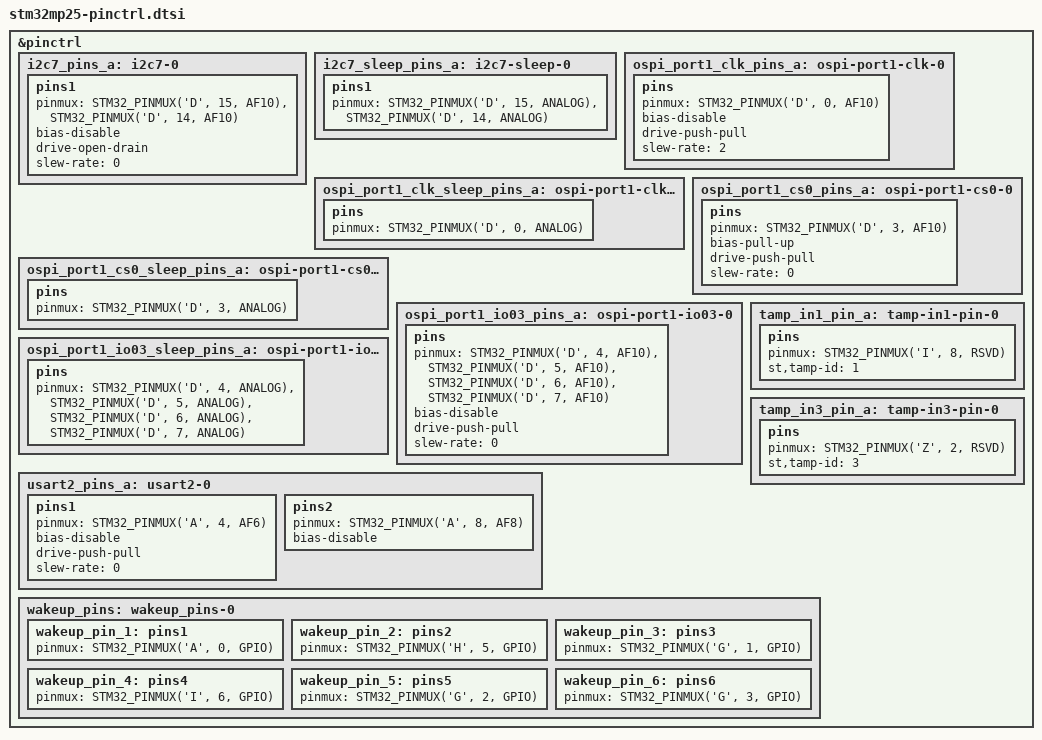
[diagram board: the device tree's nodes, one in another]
// SPDX-License-Identifier: (GPL-2.0+ OR BSD-3-Clause)
/*
 * Copyright (C) STMicroelectronics 2021 - All Rights Reserved
 * Author: Alexandre Torgue <alexandre.torgue@foss.st.com> for STMicroelectronics.
 */
#include <dt-bindings/pinctrl/stm32-pinfunc.h>

&pinctrl {
	i2c7_pins_a: i2c7-0 {
		pins1 {
			pinmux = <STM32_PINMUX('D', 15, AF10)>, /* I2C7_SCL */
				 <STM32_PINMUX('D', 14, AF10)>; /* I2C7_SDA */
			bias-disable;
			drive-open-drain;
			slew-rate = <0>;
		};
	};

	i2c7_sleep_pins_a: i2c7-sleep-0 {
		pins1 {
			pinmux = <STM32_PINMUX('D', 15, ANALOG)>, /* I2C7_SCL */
				 <STM32_PINMUX('D', 14, ANALOG)>; /* I2C7_SDA */
		};
	};

	ospi_port1_clk_pins_a: ospi-port1-clk-0 {
		pins {
			pinmux = <STM32_PINMUX('D', 0, AF10)>; /* OSPI1_CLK */
			bias-disable;
			drive-push-pull;
			slew-rate = <2>;
		};
	};

	ospi_port1_clk_sleep_pins_a: ospi-port1-clk-sleep-0 {
		pins {
			pinmux = <STM32_PINMUX('D', 0, ANALOG)>; /* OSPI1_CLK */
		};
	};

	ospi_port1_cs0_pins_a: ospi-port1-cs0-0 {
		pins {
			pinmux = <STM32_PINMUX('D', 3, AF10)>; /* OSPI_NCS0 */
			bias-pull-up;
			drive-push-pull;
			slew-rate = <0>;
		};
	};

	ospi_port1_cs0_sleep_pins_a: ospi-port1-cs0-sleep-0 {
		pins {
			pinmux = <STM32_PINMUX('D', 3, ANALOG)>; /* OSPI_NCS0 */
		};
	};

	ospi_port1_io03_pins_a: ospi-port1-io03-0 {
		pins {
			pinmux = <STM32_PINMUX('D', 4, AF10)>, /* OSPI_IO0 */
				 <STM32_PINMUX('D', 5, AF10)>, /* OSPI_IO1 */
				 <STM32_PINMUX('D', 6, AF10)>, /* OSPI_IO2 */
				 <STM32_PINMUX('D', 7, AF10)>; /* OSPI_IO3 */
			bias-disable;
			drive-push-pull;
			slew-rate = <0>;
		};
	};

	ospi_port1_io03_sleep_pins_a: ospi-port1-io03-sleep-0 {
		pins {
			pinmux = <STM32_PINMUX('D', 4, ANALOG)>, /* OSPI_IO0 */
				 <STM32_PINMUX('D', 5, ANALOG)>, /* OSPI_IO1 */
				 <STM32_PINMUX('D', 6, ANALOG)>, /* OSPI_IO2 */
				 <STM32_PINMUX('D', 7, ANALOG)>; /* OSPI_IO3 */
		};
	};

	tamp_in1_pin_a: tamp-in1-pin-0 {
		pins {
			pinmux = <STM32_PINMUX('I', 8, RSVD)>;
			st,tamp-id = <1>;
		};
	};

	tamp_in3_pin_a: tamp-in3-pin-0 {
		pins {
			pinmux = <STM32_PINMUX('Z', 2, RSVD)>;
			st,tamp-id = <3>;
		};
	};

	usart2_pins_a: usart2-0 {
		pins1 {
			pinmux = <STM32_PINMUX('A', 4, AF6)>; /* USART2_TX */
			bias-disable;
			drive-push-pull;
			slew-rate = <0>;
		};
		pins2 {
			pinmux = <STM32_PINMUX('A', 8, AF8)>; /* USART2_RX */
			bias-disable;
		};
	};

	wakeup_pins: wakeup_pins-0 {
		wakeup_pin_1: pins1 {
			pinmux = <STM32_PINMUX('A', 0, GPIO)>;
		};
		wakeup_pin_2: pins2 {
			pinmux = <STM32_PINMUX('H', 5, GPIO)>;
		};
		wakeup_pin_3: pins3 {
			pinmux = <STM32_PINMUX('G', 1, GPIO)>;
		};
		wakeup_pin_4: pins4 {
			pinmux = <STM32_PINMUX('I', 6, GPIO)>;
		};
		wakeup_pin_5: pins5 {
			pinmux = <STM32_PINMUX('G', 2, GPIO)>;
		};
		wakeup_pin_6: pins6 {
			pinmux = <STM32_PINMUX('G', 3, GPIO)>;
		};
	};
};
